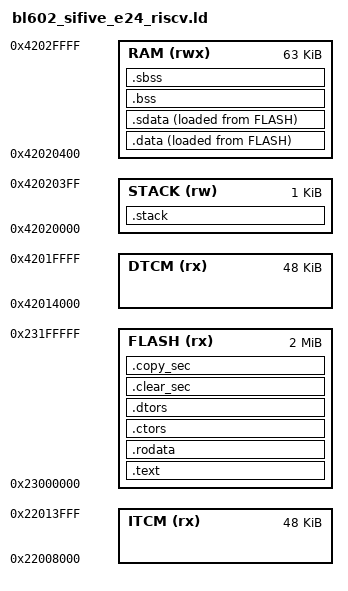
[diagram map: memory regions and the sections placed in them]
/******************************************************************************************
  Filename    : Memory_Map.ld
  
  Core        : RV32IMAC
  
  MCU         : FE310-G002 (SiFive)
    
  Author      : Chalandi Amine
 
  Owner       : Chalandi Amine
  
  Date        : 04.06.2021
  
  Description : Linker description file for FE310 SiFive
  
******************************************************************************************/

/******************************************************************************************
 ELF Entrypoint
******************************************************************************************/
ENTRY(_start)

/******************************************************************************************
 Globals
******************************************************************************************/
__FLASH_START_ADDRESS = 0x23000000;
__FLASH_SIZE          = 2M;

__ITCM_START_ADDRESS = 0x22008000;
__ITCM_SIZE          = 48K;

__DTCM_START_ADDRESS = 0x42014000;
__DTCM_SIZE          = 48K;

__STACK_START_ADDRESS = 0x42020000;
__STACK_SIZE = 1K;

__RAM_START_ADDRESS = 0x42020000 + __STACK_SIZE;
__RAM_SIZE =  64K - __STACK_SIZE;

/******************************************************************************************
 Memory configuration
******************************************************************************************/

MEMORY
{
  FLASH(rx)   : ORIGIN = __FLASH_START_ADDRESS, LENGTH = __FLASH_SIZE
  ITCM(rx)    : ORIGIN = __ITCM_START_ADDRESS,  LENGTH = __ITCM_SIZE
  DTCM(rx)    : ORIGIN = __DTCM_START_ADDRESS,  LENGTH = __DTCM_SIZE
  STACK(rw)   : ORIGIN = __STACK_START_ADDRESS, LENGTH = __STACK_SIZE
  RAM(rwx)    : ORIGIN = __RAM_START_ADDRESS,   LENGTH = __RAM_SIZE
}

/******************************************************************************************
 Sections definition
******************************************************************************************/
SECTIONS
{
  /* Program code (text) */
  .text : ALIGN(4)
  {
    PROVIDE(__CODE_BASE_ADDRESS = .);
    *(.boot)
    *(.text)
    . = ALIGN(4);
  } > FLASH

  /* Read-only data (.rodata) */
  .rodata : ALIGN(4)
  {
    PROVIDE(__RODATA_BASE_ADDRESS = .);
    *(.rodata)
  } > FLASH

 /* Section for constructors */
  .ctors : ALIGN(4)
  {
    PROVIDE(__CTOR_LIST__  = .);
    KEEP (*(SORT(.ctors.*)))
    KEEP (*(.ctors))
    KEEP (*(SORT(.init_array.*)))
    KEEP (*(.init_array))
    LONG(-1) ;
    PROVIDE(__CTOR_END__  = .);
    . = ALIGN(4);
  }  > FLASH


  /* Section for destructors */
  .dtors : ALIGN(4)
  {
    PROVIDE(__DTOR_LIST__  = .);
    KEEP (*(SORT(.dtors.*)))
    KEEP (*(.dtors))
    KEEP (*(SORT(.fini_array.*)))
    KEEP (*(.fini_array))
    LONG(-1) ;
    PROVIDE(__DTOR_END__  = .);
    . = ALIGN(4);
  } > FLASH

  /* Runtime clear table */
  .clear_sec : ALIGN(4)
  {
    PROVIDE(__RUNTIME_CLEAR_TABLE = .) ;
    LONG(0 + ADDR(.bss));   LONG(SIZEOF(.bss));
    LONG(-1);                 LONG(-1);
    . = ALIGN(4);
  } > FLASH

  /* Runtime copy table */
  .copy_sec : ALIGN(4)
  {
    PROVIDE(__RUNTIME_COPY_TABLE = .) ;
    LONG(LOADADDR(.data));   LONG(0 + ADDR(.data));   LONG(SIZEOF(.data));
    LONG(LOADADDR(.sdata));  LONG(0 + ADDR(.sdata));  LONG(SIZEOF(.sdata));
    LONG(-1);                LONG(-1);                LONG(-1);
    . = ALIGN(4);
    PROVIDE(__CODE_END_ADDRESS = .);
  } > FLASH 

  /* The ROM-to-RAM initialized data sections */
  .data : ALIGN(4) 
  {
    *(.data)
    *(.data*)
    . = ALIGN(4);
  } > RAM  AT>FLASH
  
  .sdata : ALIGN(4) 
  {
    *(.sdata)
    . = ALIGN(4);
  } > RAM  AT>FLASH

  

  /* The uninitialized (zero-cleared) data sections */
  .bss : ALIGN(4)
  {
    *(.bss)
    *(.bss*)
    . = ALIGN(4);
  } > RAM
  
  .sbss : ALIGN(4)
  {
    *(.sbss)
    . = ALIGN(4);
  } > RAM

  /* stack definition */
  .stack :
  {
    . = ALIGN(MAX(__STACK_SIZE , .), 8);
    PROVIDE(__STACK_TOP = .) ;
  } > STACK

}
